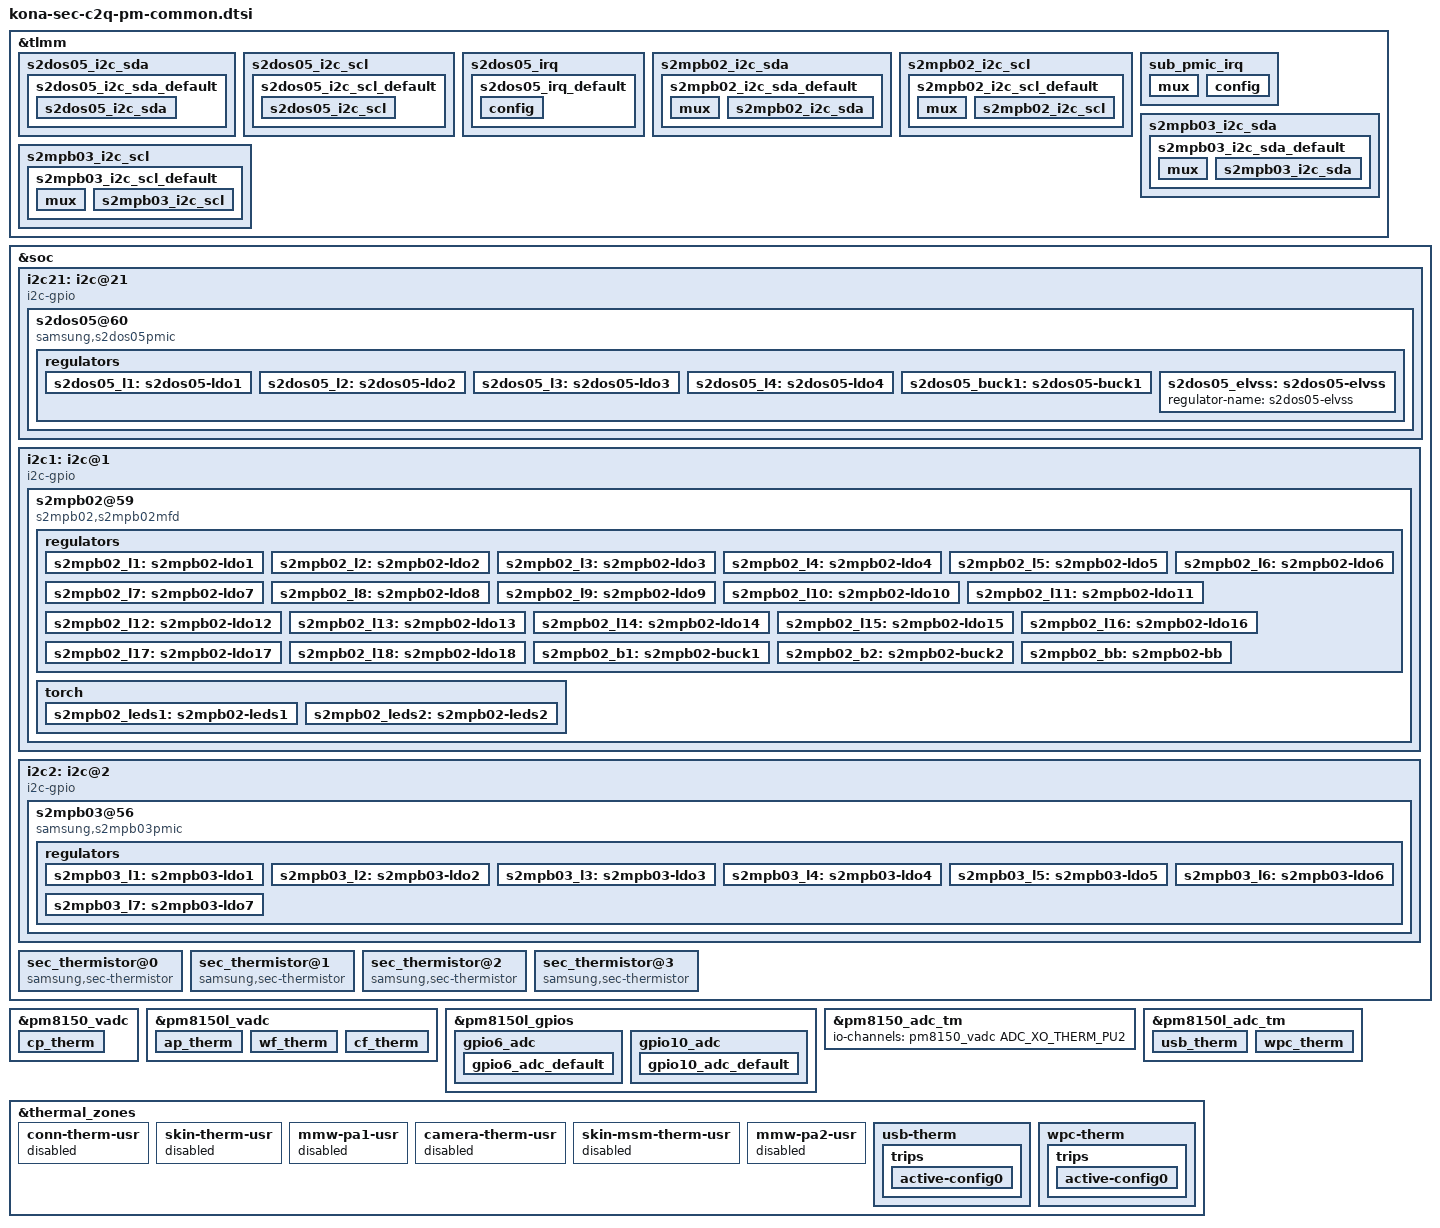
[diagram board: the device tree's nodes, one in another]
/* Copyright (c) 2014, The Linux Foundation. All rights reserved.
 *
 * This program is free software; you can redistribute it and/or modify
 * it under the terms of the GNU General Public License version 2 and
 * only version 2 as published by the Free Software Foundation.
 *
 * This program is distributed in the hope that it will be useful,
 * but WITHOUT ANY WARRANTY; without even the implied warranty of
 * MERCHANTABILITY or FITNESS FOR A PARTICULAR PURPOSE.  See the
 * GNU General Public License for more details.
 */

#include <dt-bindings/regulator/qcom,rpmh-regulator-levels.h>

&tlmm {
	s2dos05_i2c_sda {
		s2dos05_i2c_sda_default: s2dos05_i2c_sda_default {
			s2dos05_i2c_sda {
				pins = "gpio62";
				drive-strength = <2>;
				bias-disable;
			};
		};
	};
	s2dos05_i2c_scl {
		s2dos05_i2c_scl_default: s2dos05_i2c_scl_default {
			s2dos05_i2c_scl {
				pins = "gpio63";
				drive-strength = <2>;
				bias-disable;
			};
		};
	};
	s2dos05_irq {
		s2dos05_irq_default: s2dos05_irq_default {
			config {
				pins = "gpio93";
				drive-strength = <2>;
				bias-disable;
				input-enable;
			};
		};
	};

	s2mpb02_i2c_sda {
		s2mpb02_i2c_sda_default: s2mpb02_i2c_sda_default {
			mux {
				pins = "gpio98";
				function = "gpio";
			};
			s2mpb02_i2c_sda {
				pins = "gpio98";
				drive-strength = <2>;
				bias-disable;
			};
		};
	};

	s2mpb02_i2c_scl {
		s2mpb02_i2c_scl_default: s2mpb02_i2c_scl_default {
			mux {
				pins = "gpio99";
				function = "gpio";
			};
			s2mpb02_i2c_scl {
				pins = "gpio99";
				drive-strength = <2>;
				bias-disable;
			};
		};
	};

	sub_pmic_irq: sub_pmic_irq {
		mux {
			pins = "gpio109";
			function = "gpio";
		};
		config {
			pins = "gpio109";
			drive-strength = <2>;
			bias-disable;
		};
	};


	s2mpb03_i2c_sda {
		s2mpb03_i2c_sda_default: s2mpb03_i2c_sda_default {
			mux {
				pins = "gpio142";
				function = "gpio";
			};
			s2mpb03_i2c_sda {
				pins = "gpio142";
				drive-strength = <2>;
				bias-disable;
			};
		};
	};

	s2mpb03_i2c_scl {
		s2mpb03_i2c_scl_default: s2mpb03_i2c_scl_default {
			mux {
				pins = "gpio143";
				function = "gpio";
			};
			s2mpb03_i2c_scl {
				pins = "gpio143";
				drive-strength = <2>;
				bias-disable;
			};
		};
	};
};

&soc {
	/* S2DOS05 Display PMIC */
	i2c21: i2c@21 {
		cell-index = <21>;
		compatible = "i2c-gpio";
		gpios = <&tlmm 62 0 /* sda */
			&tlmm 63 0 /* scl */
		>;
		#i2c-gpio,delay-us = <2>;
		#address-cells = <1>;
		#size-cells = <0>;

		pinctrl-names = "default";
		pinctrl-0 = <&s2dos05_i2c_sda_default &s2dos05_i2c_scl_default>;

		s2dos05@60 {
			compatible = "samsung,s2dos05pmic";
			reg = <0x60>;
			adc_mode = <2>; /* 0 : disable, 1 : current meter, 2 : power meter */
			adc_sync_mode = <2>; /* 1 : sync mode, 2 : async mode */

			pinctrl-names = "default";
			pinctrl-0 = <&s2dos05_irq_default>;
			s2dos05,s2dos05_int = <&tlmm 93 0>;

			regulators {
				s2dos05_l1: s2dos05-ldo1 {
					regulator-name = "s2dos05-ldo1";
					regulator-min-microvolt = <1500000>;
					regulator-max-microvolt = <2000000>;
					regulator-active-discharge = <1>;
				};

				s2dos05_l2: s2dos05-ldo2 {
					regulator-name = "s2dos05-ldo2";
					regulator-min-microvolt = <1500000>;
					regulator-max-microvolt = <2000000>;
					regulator-active-discharge = <1>;
				};

				s2dos05_l3: s2dos05-ldo3 {
					regulator-name = "s2dos05-ldo3";
					regulator-min-microvolt = <2700000>;
					regulator-max-microvolt = <3775000>;
					regulator-active-discharge = <1>;
				};

				s2dos05_l4: s2dos05-ldo4 {
					regulator-name = "s2dos05-ldo4";
					regulator-min-microvolt = <2700000>;
					regulator-max-microvolt = <3775000>;
					regulator-active-discharge = <1>;
				};

				s2dos05_buck1: s2dos05-buck1 {
					regulator-name = "s2dos05-buck1";
					regulator-min-microvolt = <850000>;
					regulator-max-microvolt = <2100000>;
					regulator-active-discharge = <1>;
				};

				s2dos05_elvss: s2dos05-elvss {
					regulator-name = "s2dos05-elvss";
				};
			};
		};
	};

	/* S2MPB02 Camera PMIC */
	i2c1: i2c@1 {
		cell-index = <1>;
		compatible = "i2c-gpio";
		gpios = <&tlmm 98 0
			&tlmm 99 0
		>;
		i2c-gpio,delay-us = <2>;
		#address-cells = <1>;
		#size-cells = <0>;

		pinctrl-names = "default";
		pinctrl-0 = <&s2mpb02_i2c_sda_default &s2mpb02_i2c_scl_default>;

		s2mpb02@59 {
			compatible = "s2mpb02,s2mpb02mfd";
			reg = <0x59>;

			pinctrl-names = "default";
			pinctrl-0 = <&sub_pmic_irq>;
			interrupt-parent = <&tlmm>;
			status = "okay";

			regulators {
				s2mpb02_l1: s2mpb02-ldo1 {
					regulator-name = "s2mpb02-ldo1";
					regulator-min-microvolt = <1100000>;
					regulator-max-microvolt = <1100000>;
				};

				s2mpb02_l2: s2mpb02-ldo2 {
					regulator-name = "s2mpb02-ldo2";
					regulator-min-microvolt = <1000000>;
					regulator-max-microvolt = <1000000>;
				};

				s2mpb02_l3: s2mpb02-ldo3 {
					regulator-name = "s2mpb02-ldo3";
					regulator-min-microvolt = <1100000>;
					regulator-max-microvolt = <1100000>;
				};

				s2mpb02_l4: s2mpb02-ldo4 {
					regulator-name = "s2mpb02-ldo4";
					regulator-min-microvolt = <1200000>;
					regulator-max-microvolt = <1200000>;
				};

				s2mpb02_l5: s2mpb02-ldo5 {
					regulator-name = "s2mpb02-ldo5";
					regulator-min-microvolt = <1050000>;
					regulator-max-microvolt = <1050000>;
				};

				s2mpb02_l6: s2mpb02-ldo6 {
					regulator-name = "s2mpb02-ldo6";
					regulator-min-microvolt = <1800000>;
					regulator-max-microvolt = <1800000>;
				};

				s2mpb02_l7: s2mpb02-ldo7 {
					regulator-name = "s2mpb02-ldo7";
					regulator-min-microvolt = <1800000>;
					regulator-max-microvolt = <1800000>;
				};

				s2mpb02_l8: s2mpb02-ldo8 {
					regulator-name = "s2mpb02-ldo8";
					regulator-min-microvolt = <1800000>;
					regulator-max-microvolt = <1800000>;
				};

				s2mpb02_l9: s2mpb02-ldo9 {
					regulator-name = "s2mpb02-ldo9";
					regulator-min-microvolt = <1800000>;
					regulator-max-microvolt = <1800000>;
				};

				s2mpb02_l10: s2mpb02-ldo10 {
					regulator-name = "s2mpb02-ldo10";
					regulator-min-microvolt = <1800000>;
					regulator-max-microvolt = <1800000>;
				};

				s2mpb02_l11: s2mpb02-ldo11 {
					regulator-name = "s2mpb02-ldo11";
					regulator-min-microvolt = <2800000>;
					regulator-max-microvolt = <2800000>;
				};

				s2mpb02_l12: s2mpb02-ldo12 {
					regulator-name = "s2mpb02-ldo12";
					regulator-min-microvolt = <2800000>;
					regulator-max-microvolt = <2800000>;
				};

				s2mpb02_l13: s2mpb02-ldo13 {
					regulator-name = "s2mpb02-ldo13";
					regulator-min-microvolt = <2800000>;
					regulator-max-microvolt = <2800000>;
				};

				s2mpb02_l14: s2mpb02-ldo14 {
					regulator-name = "s2mpb02-ldo14";
					regulator-min-microvolt = <2800000>;
					regulator-max-microvolt = <2800000>;
				};

				s2mpb02_l15: s2mpb02-ldo15 {
					regulator-name = "s2mpb02-ldo15";
					regulator-min-microvolt = <3300000>;
					regulator-max-microvolt = <3300000>;
				};

				s2mpb02_l16: s2mpb02-ldo16 {
					regulator-name = "s2mpb02-ldo16";
					regulator-min-microvolt = <2800000>;
					regulator-max-microvolt = <2800000>;
				};

				s2mpb02_l17: s2mpb02-ldo17 {
					regulator-name = "s2mpb02-ldo17";
					regulator-min-microvolt = <2700000>;
					regulator-max-microvolt = <2700000>;
				};

				s2mpb02_l18: s2mpb02-ldo18 {
					regulator-name = "s2mpb02-ldo18";
					regulator-min-microvolt = <3400000>;
					regulator-max-microvolt = <3400000>;
				};

				s2mpb02_b1: s2mpb02-buck1 {
					regulator-name = "s2mpb02-buck1";
					regulator-min-microvolt = <1300000>;
					regulator-max-microvolt = <1300000>;
					regulator-always-on;
				};

				s2mpb02_b2: s2mpb02-buck2 {
					regulator-name = "s2mpb02-buck2";
					regulator-min-microvolt = <1300000>;
					regulator-max-microvolt = <1300000>;
					regulator-always-on;
				};

				s2mpb02_bb: s2mpb02-bb {
					regulator-name = "s2mpb02-bb";
					regulator-min-microvolt = <3500000>;
					regulator-max-microvolt = <3500000>;
					regulator-always-on;
				};
			};

			torch {
				status = "okay";
				s2mpb02_leds1: s2mpb02-leds1 {
					ledname = "leds-sec1";
					/* S2MPB02_FLASH_LED_1 */
					id = <0>;
					/* S2MPB02_FLASH_CURRENT */
					brightness = <0xA>;
					/* S2MPB02_FLASH_TIMEOUT */
					timeout = <0x7>;
					default-trigger = "flash_trigger";
					gpios = <&tlmm 117 0>;
				};

				s2mpb02_leds2: s2mpb02-leds2 {
					ledname = "torch-sec1";
					/* S2MPB02_TORCH_LED_1 */
					id = <1>;
					/* S2MPB02_TORCH_CURRENT */
					brightness = <0x9>;
					/* S2MPB02_TORCH_TIMEOUT */
					timeout = <0xF>;
					default-trigger = "torch_trigger";
					gpios = <&tlmm 136 0>;
				};
			};
		};
	};

	/* S2MPB03 Camera PMIC */
	i2c2: i2c@2 {
		cell-index = <2>;
		compatible = "i2c-gpio";
		gpios = <&tlmm 142 0 /* sda */
			&tlmm 143 0 /* scl */
		>;
		#i2c-gpio,delay-us = <2>;
		#address-cells = <1>;
		#size-cells = <0>;

		pinctrl-names = "default";
		pinctrl-0 = <&s2mpb03_i2c_sda_default &s2mpb03_i2c_scl_default>;

		/* S2MPB03 Camera PMIC */
		s2mpb03@56 {
			compatible = "samsung,s2mpb03pmic";
			reg = <0x56>;
			additional_reg_init;

			regulators {
				s2mpb03_l1: s2mpb03-ldo1 {
					regulator-name = "s2mpb03-ldo1";
					regulator-min-microvolt = <1050000>;
					regulator-max-microvolt = <1050000>;
				};

				s2mpb03_l2: s2mpb03-ldo2 {
					regulator-name = "s2mpb03-ldo2";
					regulator-min-microvolt = <1100000>;
					regulator-max-microvolt = <1100000>;
				};

				s2mpb03_l3: s2mpb03-ldo3 {
					regulator-name = "s2mpb03-ldo3";
					regulator-min-microvolt = <1800000>;
					regulator-max-microvolt = <1800000>;
				};

				s2mpb03_l4: s2mpb03-ldo4 {
					regulator-name = "s2mpb03-ldo4";
					regulator-min-microvolt = <1100000>;
					regulator-max-microvolt = <1100000>;
				};

				s2mpb03_l5: s2mpb03-ldo5 {
					regulator-name = "s2mpb03-ldo5";
					regulator-min-microvolt = <2800000>;
					regulator-max-microvolt = <2800000>;
				};

				s2mpb03_l6: s2mpb03-ldo6 {
					regulator-name = "s2mpb03-ldo6";
					regulator-min-microvolt = <2800000>;
					regulator-max-microvolt = <2800000>;
				};

				s2mpb03_l7: s2mpb03-ldo7 {
					regulator-name = "s2mpb03-ldo7";
					regulator-min-microvolt = <2800000>;
					regulator-max-microvolt = <2800000>;
				};
			};
		};
	};

	/* AP Thermistor table */
	sec_thermistor@0 {
		compatible = "samsung,sec-thermistor";
		status = "okay";
		thermistor_name = "sec-ap-thermistor";
		id = <0>;

		io-channels = <&pm8150l_vadc ADC_AMUX_THM2_PU2>;
		io-channel-names = "ap_therm";
		io-channel-ranges;
		use_iio_processed;

		adc_array = <124048 128992 133936 138879 143823 148767 154437 160108 165778 171449
			177119 184450 191781 199113 206444 213775 221872 229969 238066 246163
			254260 263654 273049 282443 291838 301232 310704 320177 329649 339122
			348594 360311 372028 383745 395462 407179 420882 434584 448287 461989
			475692 490770 505848 520925 536003 551081 568858 586635 604411 622188
			639965 658871 677776 696682 715587 734493 756137 777780 799424 821067
			842711 864692 886673 908654 930635 952616 975025 997434 1019844 1042253
			1064662 1087006 1109351 1131695 1154040 1176384 1195874 1215363 1234853 1254342
			1273832 1293724 1313616 1333507 1353399 1373291 1387811 1402331 1416851 1431371
			1445891
			1462695 1479498 1496302 1513105 1529909 1544312 1558715 1573118 1587521 1601924
			1613485 1625047 1636608 1648170 1659731 1669865 1679999 1690134 1700268 1710402>;

		temp_array = <900 890 880 870 860 850 840 830 820 810
				800 790 780 770 760 750 740 730 720 710
				700 690 680 670 660 650 640 630 620 610
				600 590 580 570 560 550 540 530 520 510
				500 490 480 470 460 450 440 430 420 410
				400 390 380 370 360 350 340 330 320 310
				300 290 280 270 260 250 240 230 220 210
				200 190 180 170 160 150 140 130 120 110
				100 90 80 70 60 50 40 30 20 10
				0
				(-10) (-20) (-30) (-40) (-50) (-60) (-70) (-80) (-90) (-100)
				(-110)(-120)(-130)(-140)(-150)(-160)(-170)(-180)(-190) (-200)>;
	};

	/* CP Thermistor table */
	sec_thermistor@1 {
		compatible = "samsung,sec-thermistor";
		status = "okay";
		thermistor_name = "sec-cp-thermistor";
		id = <1>;

		io-channels = <&pm8150_vadc ADC_AMUX_THM1_PU2>;
		io-channel-names = "cp_therm";
		io-channel-ranges;
		use_iio_processed;

		adc_array = <127130 131879 136628 141378 146127 150876 156793 162710 168627 174544
				180461 187779 195097 202416 209734 217052 225142 233233 241323 249414
				257504 266808 276111 285415 294718 304022 314844 325666 336487 347309
				358131 368966 379801 390635 401470 412305 424652 436998 449345 461691
				474038 491010 507982 524955 541927 558899 576066 593233 610400 627567
				644734 664535 684336 704137 723938 743739 764779 785819 806860 827900
				848940 870584 892227 913871 935514 957158 981072 1004987 1028901 1052816
				1076730 1100236 1123741 1147247 1170752 1194258 1213611 1232965 1252318 1271672
				1291025 1309788 1328551 1347314 1366077 1384840 1398458 1412076 1425694 1439312
				1452930
				1469773 1486615 1503458 1520300 1537143 1550904 1564665 1578425 1592186 1605947
				1618138 1630328 1642519 1654709 1666900 1677054 1687207 1697361 1707514 1717668>;

		temp_array = <900 890 880 870 860 850 840 830 820 810
				800 790 780 770 760 750 740 730 720 710
				700 690 680 670 660 650 640 630 620 610
				600 590 580 570 560 550 540 530 520 510
				500 490 480 470 460 450 440 430 420 410
				400 390 380 370 360 350 340 330 320 310
				300 290 280 270 260 250 240 230 220 210
				200 190 180 170 160 150 140 130 120 110
				100 90 80 70 60 50 40 30 20 10
				0
				(-10) (-20) (-30) (-40) (-50) (-60) (-70) (-80) (-90) (-100)
				(-110)(-120)(-130)(-140)(-150)(-160)(-170)(-180)(-190) (-200)>;
	};

	/* WiFi Thermistor table */
	sec_thermistor@2 {
		compatible = "samsung,sec-thermistor";
		status = "okay";
		thermistor_name = "sec-wf-thermistor";
		id = <2>;

		io-channels = <&pm8150l_vadc ADC_GPIO2_PU2>;
		io-channel-names = "wf_therm";
		io-channel-ranges;
		use_iio_processed;

		pinctrl-names = "default";
		pinctrl-0 = <&gpio6_adc_default>;

		adc_array = <128492 133189 137886 142584 147281 151978 157902 163825 169749 175672
				181596 188901 196207 203512 210818 218123 226181 234239 242297 250355
				258413 267742 277072 286401 295731 305060 315849 326639 337428 348218
				359007 369803 380599 391394 402190 412986 425320 437653 449987 462320
				474654 491620 508586 525551 542517 559483 576533 593583 610634 627684
				644734 664626 684518 704409 724301 744193 765214 786235 807255 828276
				849297 870947 892597 914248 935898 957548 981404 1005260 1029115 1052971
				1076827 1100404 1123981 1147558 1171135 1194712 1214052 1233393 1252733 1272074
				1291414 1310209 1329005 1347800 1366596 1385391 1398977 1412563 1426148 1439734
				1453320
				1470123 1486927 1503730 1520534 1537337 1551130 1564924 1578717 1592511 1606304
				1618488 1630672 1642857 1655041 1667225 1677346 1687467 1697588 1707709 1717830>;

		temp_array = <900 890 880 870 860 850 840 830 820 810
				800 790 780 770 760 750 740 730 720 710
				700 690 680 670 660 650 640 630 620 610
				600 590 580 570 560 550 540 530 520 510
				500 490 480 470 460 450 440 430 420 410
				400 390 380 370 360 350 340 330 320 310
				300 290 280 270 260 250 240 230 220 210
				200 190 180 170 160 150 140 130 120 110
				100 90 80 70 60 50 40 30 20 10
				0
				(-10) (-20) (-30) (-40) (-50) (-60) (-70) (-80) (-90) (-100)
				(-110)(-120)(-130)(-140)(-150)(-160)(-170)(-180)(-190) (-200)>;
	};

	/* Camera Flash Thermistor table */
	sec_thermistor@3 {
		compatible = "samsung,sec-thermistor";
		status = "okay";
		thermistor_name = "sec-cf-thermistor";
		id = <3>;

		io-channels = <&pm8150l_vadc ADC_GPIO4_PU2>;
		io-channel-names = "cf_therm";
		io-channel-ranges;
		use_iio_processed;

		pinctrl-names = "default";
		pinctrl-0 = <&gpio10_adc_default>;

		adc_array = <107309 111980 116652 121323 125995 130666 136453 142240 148028 153815
				159602 166583 173564 180544 187525 194506 201811 209117 216422 223728
				231033 240324 249615 258905 268196 277487 287556 297625 307695 317764
				327833 339836 351838 363841 375843 387846 401847 415848 429848 443849
				457850 473447 489044 504640 520237 535834 554208 572582 590955 609329
				627703 646258 664814 683369 701925 720480 740839 761198 781557 801916
				822275 844645 867015 889386 911756 934126 949982 965839 981695 997552
				1013408 1036816 1060224 1083633 1107041 1130449 1151755 1173061 1194368 1215674
				1236980 1256353 1275726 1295099 1314472 1333845 1348378 1362911 1377443 1391976
				1406509
				1425700 1444891 1464083 1483274 1502465 1516388 1530311 1544234 1558157 1572080
				1585640 1599199 1612759 1626318 1639878 1650635 1661392 1672149 1682906 1693663>;

		temp_array = <900 890 880 870 860 850 840 830 820 810
				800 790 780 770 760 750 740 730 720 710
				700 690 680 670 660 650 640 630 620 610
				600 590 580 570 560 550 540 530 520 510
				500 490 480 470 460 450 440 430 420 410
				400 390 380 370 360 350 340 330 320 310
				300 290 280 270 260 250 240 230 220 210
				200 190 180 170 160 150 140 130 120 110
				100 90 80 70 60 50 40 30 20 10
				0
				(-10) (-20) (-30) (-40) (-50) (-60) (-70) (-80) (-90) (-100)
				(-110)(-120)(-130)(-140)(-150)(-160)(-170)(-180)(-190) (-200)>;
	};
};

&pm8150_vadc {
	/delete-node/ skin_therm;
	cp_therm {
		reg = <ADC_AMUX_THM1_PU2>;
		label = "cp_therm";
		qcom,ratiometric;
		qcom,hw-settle-time = <200>;
		qcom,pre-scaling = <1 1>;
		qcom,decimation = <840>;
		qcom,avg-samples = <8>;
	};
};

&pm8150l_vadc {
	/delete-node/ skin_msm_therm;
	ap_therm {
		reg = <ADC_AMUX_THM2_PU2>;
		label = "ap_therm";
		qcom,ratiometric;
		qcom,hw-settle-time = <200>;
		qcom,pre-scaling = <1 1>;
		qcom,decimation = <840>;
		qcom,avg-samples = <8>;
	};

	wf_therm {
		reg = <ADC_GPIO2_PU2>;
		label = "wf_therm";
		qcom,ratiometric;
		qcom,hw-settle-time = <200>;
		qcom,pre-scaling = <1 1>;
		qcom,decimation = <840>;
		qcom,avg-samples = <8>;
	};

	cf_therm {
		reg = <ADC_GPIO4_PU2>;
		label = "cf_therm";
		qcom,ratiometric;
		qcom,hw-settle-time = <200>;
		qcom,pre-scaling = <1 1>;
		qcom,decimation = <840>;
		qcom,avg-samples = <8>;
	};
};

&pm8150l_gpios {
	gpio6_adc {
		gpio6_adc_default: gpio6_adc_default {
			pins = "gpio6";
			function = "normal";
			bias-high-impedance;
		};
	};

	gpio10_adc {
		gpio10_adc_default: gpio10_adc_default {
			pins = "gpio10";
			function = "normal";
			bias-high-impedance;
		};
	};
};

&pm8150_adc_tm {
	io-channels = <&pm8150_vadc ADC_XO_THERM_PU2>;
	/delete-node/ skin_therm@4d;
	/delete-node/ pa_therm1@4e;
};

&pm8150l_adc_tm {
	io-channels = <&pm8150l_vadc ADC_AMUX_THM1_PU2>,
			<&pm8150l_vadc ADC_GPIO1_PU2>;

	/delete-node/ camera_flash_therm@4d;
	/delete-node/ skin_msm_therm@4e;
	/delete-node/ pa_therm2@4f;

	usb_therm {
		reg = <ADC_AMUX_THM1_PU2>;
		qcom,ratiometric;
		qcom,hw-settle-time = <200>;
	};

	wpc_therm {
		reg = <ADC_GPIO1_PU2>;
		qcom,ratiometric;
		qcom,hw-settle-time = <200>;
	};
};

&thermal_zones {
	conn-therm-usr {
		status = "disabled"; 
	};
	skin-therm-usr {
		status = "disabled"; 
	};
	mmw-pa1-usr {
		status = "disabled"; 
	};
	camera-therm-usr {
		status = "disabled"; 
	};
	skin-msm-therm-usr {
		status = "disabled";
	};
	mmw-pa2-usr {
		status = "disabled"; 
	};

	usb-therm {
		polling-delay-passive = <0>;
		polling-delay = <0>;
		thermal-governor = "user_space";
		thermal-sensors = <&pm8150l_adc_tm ADC_AMUX_THM1_PU2>;
		trips {
			active-config0 {
				temperature = <85000>;
				hysteresis = <15000>;
				type = "passive";
			};
		};
	};

	wpc-therm {
		polling-delay-passive = <0>;
		polling-delay = <0>;
		thermal-governor = "user_space";
		thermal-sensors = <&pm8150l_adc_tm ADC_GPIO1_PU2>;
		trips {
			active-config0 {
				temperature = <85000>;
				hysteresis = <15000>;
				type = "passive";
			};
		};
	};
};
